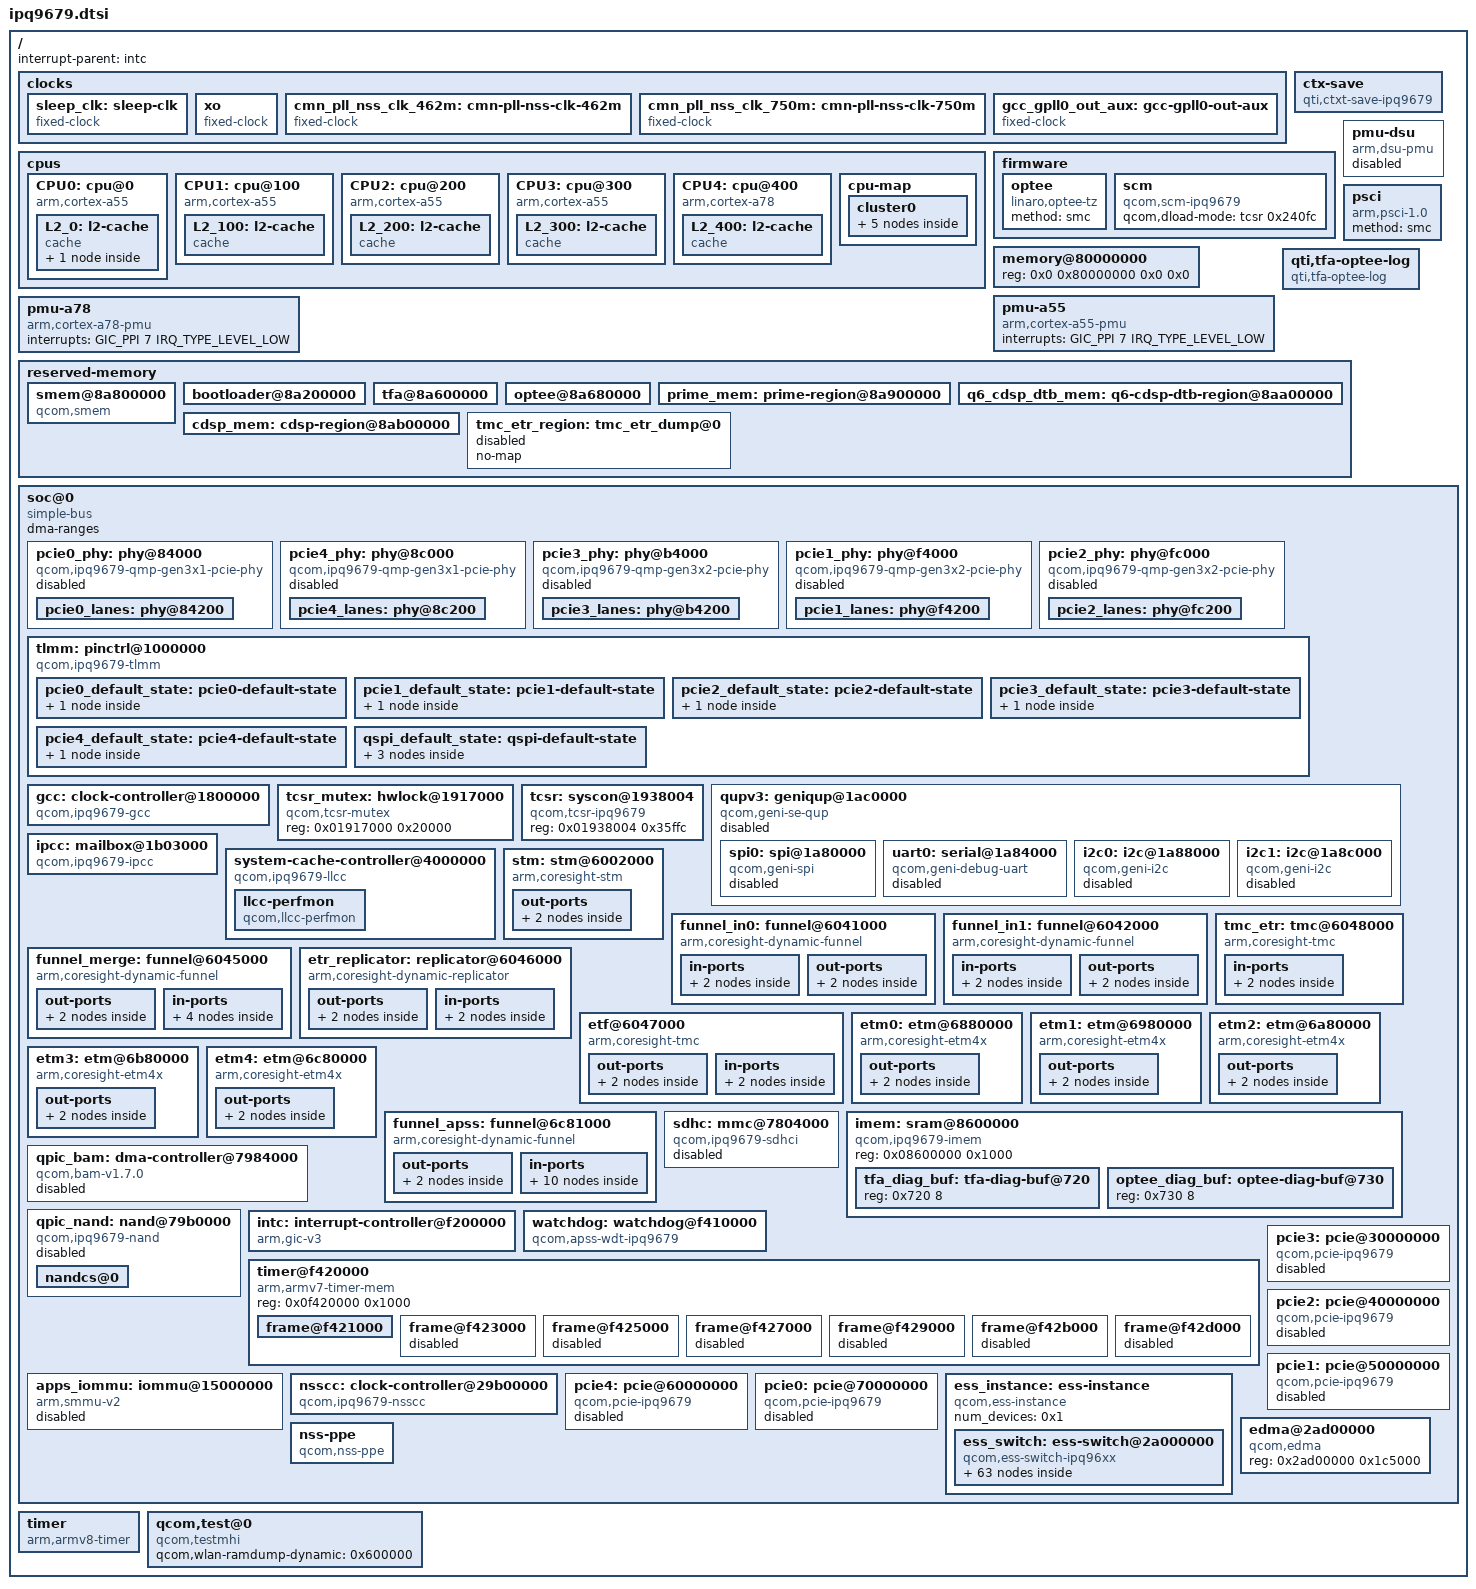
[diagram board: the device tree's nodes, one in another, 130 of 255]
// SPDX-License-Identifier: (GPL-2.0+ OR BSD-3-Clause)
/*
 * IPQ9679 device tree source
 *
 * Copyright (c) 2020-2021 The Linux Foundation. All rights reserved.
 * Copyright (c) Qualcomm Technologies, Inc. and/or its subsidiaries.
 */

#include <dt-bindings/clock/qcom,ipq9679-gcc.h>
#include <dt-bindings/clock/qcom,ipq9679-nsscc.h>
#include <dt-bindings/reset/qcom,ipq9679-gcc.h>
#include <dt-bindings/reset/qcom,ipq9679-nsscc.h>
#include <dt-bindings/interrupt-controller/arm-gic.h>
#include <dt-bindings/gpio/gpio.h>

/ {
	#address-cells = <2>;
	#size-cells = <2>;
	interrupt-parent = <&intc>;

	clocks {
		sleep_clk: sleep-clk {
			compatible = "fixed-clock";
			#clock-cells = <0>;
		};

		xo: xo {
			compatible = "fixed-clock";
			#clock-cells = <0>;
		};

		cmn_pll_nss_clk_462m: cmn-pll-nss-clk-462m {
			compatible = "fixed-clock";
			#clock-cells = <0>;
		};

		cmn_pll_nss_clk_750m: cmn-pll-nss-clk-750m {
			compatible = "fixed-clock";
			#clock-cells = <0>;
		};

		gcc_gpll0_out_aux: gcc-gpll0-out-aux {
			compatible = "fixed-clock";
			#clock-cells = <0>;
		};
	};

	cpus: cpus {
		#address-cells = <1>;
		#size-cells = <0>;

		CPU0: cpu@0 {
			device_type = "cpu";
			compatible = "arm,cortex-a55";
			reg = <0x0>;
			enable-method = "psci";
			next-level-cache = <&L2_0>;
			L2_0: l2-cache {
				compatible = "cache";
				cache-level = <2>;
				cache-unified;
				next-level-cache = <&L3_0>;
				L3_0: l3-cache {
					compatible = "cache";
					cache-level = <3>;
					cache-unified;
				};
			};
		};

		CPU1: cpu@100 {
			device_type = "cpu";
			compatible = "arm,cortex-a55";
			reg = <0x100>;
			enable-method = "psci";
			next-level-cache = <&L2_100>;
			L2_100: l2-cache {
				compatible = "cache";
				cache-level = <2>;
				cache-unified;
				next-level-cache = <&L3_0>;
			};
		};

		CPU2: cpu@200 {
			device_type = "cpu";
			compatible = "arm,cortex-a55";
			reg = <0x200>;
			enable-method = "psci";
			next-level-cache = <&L2_200>;
			L2_200: l2-cache {
				compatible = "cache";
				cache-level = <2>;
				cache-unified;
				next-level-cache = <&L3_0>;
			};
		};

		CPU3: cpu@300 {
			device_type = "cpu";
			compatible = "arm,cortex-a55";
			reg = <0x300>;
			enable-method = "psci";
			next-level-cache = <&L2_300>;
			L2_300: l2-cache {
				compatible = "cache";
				cache-level = <2>;
				cache-unified;
				next-level-cache = <&L3_0>;
			};
		};

		CPU4: cpu@400 {
			device_type = "cpu";
			compatible = "arm,cortex-a78";
			reg = <0x400>;
			enable-method = "psci";
			next-level-cache = <&L2_400>;
			L2_400: l2-cache {
				compatible = "cache";
				cache-level = <2>;
				cache-unified;
				next-level-cache = <&L3_0>;
			};
		};

		cpu-map {
			cluster0 {
				core0 {
					cpu = <&CPU0>;
				};

				core1 {
					cpu = <&CPU1>;
				};

				core2 {
					cpu = <&CPU2>;
				};

				core3 {
					cpu = <&CPU3>;
				};

				core4 {
					cpu = <&CPU4>;
				};
			};
		};
	};

	ctx-save {
		compatible = "qti,ctxt-save-ipq9679";
	};

	firmware {
		optee {
			compatible = "linaro,optee-tz";
			method = "smc";
		};

		scm {
			compatible = "qcom,scm-ipq9679", "qcom,scm";
			qcom,dload-mode = <&tcsr 0x240fc>;
		};
	};

	memory@80000000 {
		device_type = "memory";
		/* We expect the bootloader to fill in the size */
		reg = <0x0 0x80000000 0x0 0x0 >;
	};

	pmu-a55 {
		compatible = "arm,cortex-a55-pmu";
		interrupts = <GIC_PPI 7 IRQ_TYPE_LEVEL_LOW>;
	};

	pmu-a78 {
		compatible = "arm,cortex-a78-pmu";
		interrupts = <GIC_PPI 7 IRQ_TYPE_LEVEL_LOW>;
	};

	pmu-dsu {
		compatible = "arm,dsu-pmu";
		interrupts = <GIC_SPI 50 IRQ_TYPE_EDGE_RISING>;
		cpus = <&CPU0>, <&CPU1>, <&CPU2>, <&CPU3>, <&CPU4>;
		status = "disabled";
	};

	psci {
		compatible = "arm,psci-1.0";
		method = "smc";
	};

	qti,tfa-optee-log {
		compatible = "qti,tfa-optee-log";
		interrupts = <GIC_SPI 56 IRQ_TYPE_EDGE_RISING>;
		tfa-diag-info =<&tfa_diag_buf>;
		optee-diag-info =<&optee_diag_buf>;
	};

	reserved-memory {
		#address-cells = <2>;
		#size-cells = <2>;
		ranges;

		smem@8a800000 {
			compatible = "qcom,smem";
			reg = <0x0 0x8a100000 0x0 0x40000>;
			no-map;

			hwlocks = <&tcsr_mutex 3>;
		};

		bootloader@8a200000 {
			reg = <0x0 0x8a200000 0x0 0x400000>;
			no-map;
		};

		tfa@8a600000 {
			reg = <0x0 0x8a600000 0x0 0x80000>;
			no-map;
		};

		optee@8a680000 {
			reg = <0x0 0x8a680000 0x0 0x280000>;
			no-map;
		};

		prime_mem: prime-region@8a900000  {
			reg = <0x0 0x8a900000  0x0 0x100000>;
			no-map;
		};

		q6_cdsp_dtb_mem: q6-cdsp-dtb-region@8aa00000 {
			reg = <0x0 0x8aa00000 0x0 0x80000>;
			no-map;
		};

		cdsp_mem: cdsp-region@8ab00000 {
			reg = <0x0 0x8ab00000 0x0 0x2000000>;
			no-map;
		};

		tmc_etr_region: tmc_etr_dump@0 {
			no-map;
			status = "disabled";
		};
	};

	soc@0 {
		compatible = "simple-bus";
		#address-cells = <1>;
		#size-cells = <1>;
		ranges = <0 0 0 0xffffffff>;
		dma-ranges;

		pcie0_phy: phy@84000 {
			compatible = "qcom,ipq9679-qmp-gen3x1-pcie-phy",
				     "qcom,ipq9574-qmp-gen3x1-pcie-phy";
			reg = <0x00084000 0x1c0>; /* Serdes PLL */
			#address-cells = <1>;
			#size-cells = <1>;
			ranges;

			clocks = <&gcc GCC_PCIE0_AUX_CLK>,
				 <&gcc GCC_PCIE0_AHB_CLK>,
				 <&gcc GCC_ANOC_PCIE0_1LANE_M_CLK>,
				 <&gcc GCC_ANOC_PCIE0_1LANE_S_CLK>;
			clock-names = "aux", "cfg_ahb", "anoc_lane", "snoc_lane";

			assigned-clocks = <&gcc GCC_PCIE0_AUX_CLK>,
					  <&gcc GCC_PCIE0_AHB_CLK>,
					  <&gcc GCC_ANOC_PCIE0_1LANE_M_CLK>,
					  <&gcc GCC_ANOC_PCIE0_1LANE_S_CLK>;
			assigned-clock-rates = <20000000>,
					       <100000000>,
					       <200000000>,
					       <200000000>;

			resets = <&gcc GCC_PCIE0_PHY_BCR>,
				 <&gcc GCC_PCIE0PHY_PHY_BCR>;
			reset-names = "phy", "common";

			status = "disabled";

			pcie0_lanes: phy@84200 {
				reg = <0x00084200 0x170>, /* Serdes Tx0 */
				      <0x00084400 0x200>, /* Serdes Rx0 */
				      <0x00084600 0x1f0>, /* PCS: Lane0, COM, PCIE */
				      <0x00084a00 0x0f4>; /* pcs_misc */

				#phy-cells = <0>;

				clocks = <&gcc GCC_PCIE0_PIPE_CLK>;
				clock-names = "pipe0";
				clock-output-names = "gcc_pcie0_pipe_clk_src";
				#clock-cells = <0>;
			};
		};

		pcie4_phy: phy@8c000 {
			compatible = "qcom,ipq9679-qmp-gen3x1-pcie-phy",
				     "qcom,ipq9574-qmp-gen3x1-pcie-phy";
			reg = <0x0008c000 0x1c0>; /* Serdes PLL */
			#address-cells = <1>;
			#size-cells = <1>;
			ranges;

			clocks = <&gcc GCC_PCIE4_AUX_CLK>,
				 <&gcc GCC_PCIE4_AHB_CLK>,
				 <&gcc GCC_ANOC_PCIE4_1LANE_M_CLK>,
				 <&gcc GCC_ANOC_PCIE4_1LANE_S_CLK>;
			clock-names = "aux", "cfg_ahb", "anoc_lane", "snoc_lane";

			assigned-clocks = <&gcc GCC_PCIE4_AUX_CLK>,
					  <&gcc GCC_PCIE4_AHB_CLK>,
					  <&gcc GCC_ANOC_PCIE4_1LANE_M_CLK>,
					  <&gcc GCC_ANOC_PCIE4_1LANE_S_CLK>;
			assigned-clock-rates = <20000000>,
					       <100000000>,
					       <200000000>,
					       <200000000>;

			resets = <&gcc GCC_PCIE4_PHY_BCR>,
				 <&gcc GCC_PCIE4PHY_PHY_BCR>;
			reset-names = "phy", "common";

			status = "disabled";

			pcie4_lanes: phy@8c200 {
				reg = <0x0008c200 0x170>, /* Serdes Tx0 */
				      <0x0008c400 0x200>, /* Serdes Rx0 */
				      <0x0008c600 0x1f0>, /* PCS: Lane0, COM, PCIE */
				      <0x0008ca00 0x0f4>; /* pcs_misc */

				#phy-cells = <0>;

				clocks = <&gcc GCC_PCIE4_PIPE_CLK>;
				clock-names = "pipe0";
				clock-output-names = "gcc_pcie4_pipe_clk_src";
				#clock-cells = <0>;
			};
		};

		pcie3_phy: phy@b4000 {
			compatible = "qcom,ipq9679-qmp-gen3x2-pcie-phy",
				     "qcom,ipq9574-qmp-gen3x2-pcie-phy";
			reg = <0x000b4000 0x1c0>; /* Serdes PLL */
			#address-cells = <1>;
			#size-cells = <1>;
			ranges;

			clocks = <&gcc GCC_PCIE3_AUX_CLK>,
				 <&gcc GCC_PCIE3_AHB_CLK>,
				 <&gcc GCC_ANOC_PCIE3_2LANE_M_CLK>,
				 <&gcc GCC_ANOC_PCIE3_2LANE_S_CLK>;
			clock-names = "aux", "cfg_ahb", "anoc_lane", "snoc_lane";

			assigned-clocks = <&gcc GCC_PCIE3_AUX_CLK>,
					  <&gcc GCC_PCIE3_AHB_CLK>,
					  <&gcc GCC_ANOC_PCIE3_2LANE_M_CLK>,
					  <&gcc GCC_ANOC_PCIE3_2LANE_S_CLK>;
			assigned-clock-rates = <20000000>,
					       <100000000>,
					       <266666666>,
					       <200000000>;

			resets = <&gcc GCC_PCIE3_PHY_BCR>,
				 <&gcc GCC_PCIE3PHY_PHY_BCR>;
			reset-names = "phy", "common";

			status = "disabled";

			pcie3_lanes: phy@b4200 {
				reg = <0x000b4200 0x170>, /* Serdes Tx0 */
				      <0x000b4400 0x200>, /* Serdes Rx0 */
				      <0x000b4a00 0x1f0>, /* PCS: Lane0, COM, PCIE */
				      <0x000b4600 0x170>, /* Serdes Tx1 */
				      <0x000b4800 0x200>, /* Serdes Rx1 */
				      <0x000b4e00 0x0f4>; /* pcs_misc */

				#phy-cells = <0>;

				clocks = <&gcc GCC_PCIE3_PIPE_CLK>;
				clock-names = "pipe0";
				clock-output-names = "gcc_pcie3_pipe_clk_src";
				#clock-cells = <0>;
			};
		};

		pcie1_phy: phy@f4000 {
			compatible = "qcom,ipq9679-qmp-gen3x2-pcie-phy",
				     "qcom,ipq9574-qmp-gen3x2-pcie-phy";
			reg = <0x000f4000 0x1c0>; /* Serdes PLL */
			#address-cells = <1>;
			#size-cells = <1>;
			ranges;

			clocks = <&gcc GCC_PCIE1_AUX_CLK>,
				 <&gcc GCC_PCIE1_AHB_CLK>,
				 <&gcc GCC_ANOC_PCIE1_2LANE_M_CLK>,
				 <&gcc GCC_ANOC_PCIE1_2LANE_S_CLK>;
			clock-names = "aux", "cfg_ahb", "anoc_lane", "snoc_lane";

			assigned-clocks = <&gcc GCC_PCIE1_AUX_CLK>,
					  <&gcc GCC_PCIE1_AHB_CLK>,
					  <&gcc GCC_ANOC_PCIE1_2LANE_M_CLK>,
					  <&gcc GCC_ANOC_PCIE1_2LANE_S_CLK>;
			assigned-clock-rates = <20000000>,
					       <100000000>,
					       <266666666>,
					       <200000000>;

			resets = <&gcc GCC_PCIE1_PHY_BCR>,
				 <&gcc GCC_PCIE1PHY_PHY_BCR>;
			reset-names = "phy", "common";

			status = "disabled";

			pcie1_lanes: phy@f4200 {
				reg = <0x000f4200 0x170>, /* Serdes Tx0 */
				      <0x000f4400 0x200>, /* Serdes Rx0 */
				      <0x000f4a00 0x1f0>, /* PCS: Lane0, COM, PCIE */
				      <0x000f4600 0x170>, /* Serdes Tx1 */
				      <0x000f4800 0x200>, /* Serdes Rx1 */
				      <0x000f4e00 0x0f4>; /* pcs_misc */

				#phy-cells = <0>;

				clocks = <&gcc GCC_PCIE1_PIPE_CLK>;
				clock-names = "pipe0";
				clock-output-names = "gcc_pcie1_pipe_clk_src";
				#clock-cells = <0>;
			};
		};

		pcie2_phy: phy@fc000 {
			compatible = "qcom,ipq9679-qmp-gen3x2-pcie-phy",
				     "qcom,ipq9574-qmp-gen3x2-pcie-phy";
			reg = <0x000fc000 0x1c0>; /* Serdes PLL PCIE_2_CFG_QSERDES_PLL_QSERDES_PLL_G3X2_QMP_PLL */
			#address-cells = <1>;
			#size-cells = <1>;
			ranges;

			clocks = <&gcc GCC_PCIE2_AUX_CLK>,
				 <&gcc GCC_PCIE2_AHB_CLK>,
				 <&gcc GCC_ANOC_PCIE2_2LANE_M_CLK>,
				 <&gcc GCC_ANOC_PCIE2_2LANE_S_CLK>;
			clock-names = "aux", "cfg_ahb", "anoc_lane", "snoc_lane";

			assigned-clocks = <&gcc GCC_PCIE2_AUX_CLK>,
					  <&gcc GCC_PCIE2_AHB_CLK>,
					  <&gcc GCC_ANOC_PCIE2_2LANE_M_CLK>,
					  <&gcc GCC_ANOC_PCIE2_2LANE_S_CLK>;
			assigned-clock-rates = <20000000>,
					       <100000000>,
					       <266666666>,
					       <200000000>;

			resets = <&gcc GCC_PCIE2_PHY_BCR>,
				 <&gcc GCC_PCIE2PHY_PHY_BCR>;
			reset-names = "phy", "common";

			status = "disabled";

			pcie2_lanes: phy@fc200 {
				reg = <0x000fc200 0x170>, /* Serdes Tx0 */
				      <0x000fc400 0x200>, /* Serdes Rx0 */
				      <0x000fca00 0x1f0>, /* PCS: Lane0, COM, PCIE */
				      <0x000fc600 0x170>, /* Serdes Tx1 */
				      <0x000fc800 0x200>, /* Serdes Rx1 */
				      <0x000fce00 0x0f4>; /* pcs_misc */

				#phy-cells = <0>;

				clocks = <&gcc GCC_PCIE2_PIPE_CLK>;
				clock-names = "pipe0";
				clock-output-names = "gcc_pcie2_pipe_clk_src";
				#clock-cells = <0>;
			};
		};

		tlmm: pinctrl@1000000 {
			compatible = "qcom,ipq9679-tlmm";
			reg = <0x01000000 0x300000>;
			interrupts = <GIC_SPI 84 IRQ_TYPE_LEVEL_HIGH>;
			gpio-controller;
			#gpio-cells = <2>;
			gpio-ranges = <&tlmm 0 0 54>;
			interrupt-controller;
			#interrupt-cells = <2>;

			pcie0_default_state: pcie0-default-state {
				perst-n-pins {
					pins = "gpio25";
					function = "gpio";
					drive-strength = <2>;
					bias-pull-down;
					output-low;
				};
			};

			pcie1_default_state: pcie1-default-state {
				perst-n-pins {
					pins = "gpio28";
					function = "gpio";
					drive-strength = <2>;
					bias-pull-down;
					output-low;
				};
			};

			pcie2_default_state: pcie2-default-state {
				perst-n-pins {
					pins = "gpio52";
					function = "gpio";
					drive-strength = <2>;
					bias-pull-down;
					output-low;
				};
			};

			pcie3_default_state: pcie3-default-state {
				perst-n-pins {
					pins = "gpio41";
					function = "gpio";
					drive-strength = <2>;
					bias-pull-down;
					output-low;
				};
			};

			pcie4_default_state: pcie4-default-state {
				perst-n-pins {
					pins = "gpio31";
					function = "gpio";
					drive-strength = <2>;
					bias-pull-down;
					output-low;
				};
			};

			qspi_default_state: qspi-default-state {
				qspi_clk {
					pins = "gpio5";
					function = "qspi_clk";
					drive-strength = <8>;
					bias-pull-down;
				};

				qspi_cs {
					pins = "gpio4";
					function = "qspi_cs_n";
					drive-strength = <8>;
					bias-pull-up;
				};

				qspi_data {
					pins = "gpio0", "gpio1", "gpio2", "gpio3";
					function = "qspi_data";
					drive-strength = <8>;
					bias-pull-down;
				};
			};
		};

		gcc: clock-controller@1800000 {
			compatible = "qcom,ipq9679-gcc";
			reg = <0x01800000 0x40000>;

			clocks = <&xo>,
				 <&sleep_clk>;
			#clock-cells = <1>;
			#reset-cells = <1>;
			#power-domain-cells = <1>;
		};

		tcsr_mutex: hwlock@1917000 {
			compatible = "qcom,tcsr-mutex";
			reg = <0x01917000 0x20000>;
			#hwlock-cells = <1>;
		};

		tcsr: syscon@1938004 {
			compatible = "qcom,tcsr-ipq9679", "syscon";
			reg = <0x01938004 0x35ffc>;
		};

		qupv3: geniqup@1ac0000 {
			compatible = "qcom,geni-se-qup";
			reg = <0x01ac0000 0x2000>;
			clocks = <&gcc GCC_QUPV3_AHB_MST_CLK>,
				 <&gcc GCC_QUPV3_AHB_SLV_CLK>;
			clock-names = "m-ahb", "s-ahb";
			ranges;
			#address-cells = <1>;
			#size-cells = <1>;

			status = "disabled";

			spi0: spi@1a80000 {
				compatible = "qcom,geni-spi";
				reg = <0x01a80000 0x4000>;
				clocks = <&gcc GCC_QUPV3_SPI0_CLK>;
				clock-names = "se";
				interrupts = <GIC_SPI 339 IRQ_TYPE_LEVEL_HIGH>;
				assigned-clocks = <&gcc GCC_QUPV3_SPI0_CLK>;
				assigned-clock-rates = <50000000>;
				/* Use common SE TX FIFO depth configuration */
				qup-tx-fifo-depth = <0x20>;
				status = "disabled";
			};

			uart0: serial@1a84000 {
				compatible = "qcom,geni-debug-uart";
				reg = <0x01a84000 0x4000>;
				clocks = <&gcc GCC_QUPV3_UART0_CLK>;
				clock-names = "se";
				interrupts = <GIC_SPI 340 IRQ_TYPE_LEVEL_HIGH>;
				status = "disabled";
			};

			i2c0: i2c@1a88000 {
				compatible = "qcom,geni-i2c";
				reg = <0x1a88000 0x4000>;
				clocks = <&gcc GCC_QUPV3_I2C0_CLK>;
				clock-names = "se";
				clock-frequency = <400000>;
				interrupts = <GIC_SPI 341 IRQ_TYPE_LEVEL_HIGH>;
				assigned-clocks = <&gcc GCC_QUPV3_I2C0_CLK>;
				assigned-clock-rates = <64000000>;
				status = "disabled";
			};

			i2c1: i2c@1a8c000 {
				compatible = "qcom,geni-i2c";
				reg = <0x1a8c000 0x4000>;
				clocks = <&gcc GCC_QUPV3_I2C1_CLK>;
				clock-names = "se";
				clock-frequency = <400000>;
				interrupts = <GIC_SPI 342 IRQ_TYPE_LEVEL_HIGH>;
				assigned-clocks = <&gcc GCC_QUPV3_I2C1_CLK>;
				assigned-clock-rates = <64000000>;
				status = "disabled";
			};
		};

		ipcc: mailbox@1b03000 {
			compatible = "qcom,ipq9679-ipcc", "qcom,ipcc";
			reg = <0x01b03000 0x1000>;
			interrupts = <GIC_SPI 445 IRQ_TYPE_LEVEL_HIGH>;
			interrupt-controller;
			#interrupt-cells = <3>;
			#mbox-cells = <2>;
		};

		system-cache-controller@4000000 {
			compatible = "qcom,ipq9679-llcc";
			reg = <0x04000000 0x200000>, <0x04000000 0x200000>;
			reg-names = "llcc_base", "llcc_broadcast_base";
			interrupts = <GIC_SPI 68 IRQ_TYPE_LEVEL_HIGH>;

			llcc-perfmon {
				compatible = "qcom,llcc-perfmon";
			};
		};

		stm: stm@6002000 {
			compatible = "arm,coresight-stm", "arm,primecell";
			reg = <0x06002000 0x1000>,
				<0x09000000 0x1000000>;
			reg-names = "stm-base", "stm-stimulus-base";
			coresight-name = "coresight-stm";
			clocks = <&gcc GCC_QDSS_DAP_CLK>,
				 <&gcc GCC_QDSS_AT_CLK>;
			clock-names = "apb_pclk", "atclk";

			out-ports {
				port {
					stm_out: endpoint {
						remote-endpoint = <&funnel0_in7>;
					};
				};
			};
		};

		funnel_in0: funnel@6041000 {
			compatible = "arm,coresight-dynamic-funnel", "arm,primecell";
			reg = <0x06041000 0x1000>;
			reg-names = "funnel-base";
			coresight-name = "coresight-funnel-in0";
			clocks = <&gcc GCC_QDSS_DAP_CLK>,
				 <&gcc GCC_QDSS_AT_CLK>;
			clock-names = "apb_pclk", "atclk";

			in-ports {
				#address-cells = <1>;
				#size-cells = <0>;

				/*
				 * Port 0 - TME
				 * Port 2 - SNOC
				 * Port 3 - NSS
				 * Port 4 - CNOC
				 * Port 6 - TPDA QDSS
				 * Port 7 - STM_SS
				 */

				port@7 {
					reg = <7>;
					funnel0_in7: endpoint {
						remote-endpoint = <&stm_out>;
					};
				};
			};

			out-ports {
				port {
					funnel0_out: endpoint {
						remote-endpoint = <&merge_funnel_in0>;
					};
				};
			};
		};

		funnel_in1: funnel@6042000 {
			compatible = "arm,coresight-dynamic-funnel", "arm,primecell";
			reg = <0x06042000 0x1000>;
			reg-names = "funnel-base";
			coresight-name = "coresight-funnel-in1";
			clocks = <&gcc GCC_QDSS_DAP_CLK>,
				 <&gcc GCC_QDSS_AT_CLK>;
			clock-names = "apb_pclk", "atclk";

			in-ports {
				#address-cells = <1>;
				#size-cells = <0>;

				/*
				 * Port 0 - AGGRENOC
				 * Port 1 & 2 - DDRSS
				 * Port 3 - TPDA QDSS
				 * Port 4 - APSS
				 * Port 5 - TURING
				 */

				port@4 {
					reg = <4>;
					funnel1_in2: endpoint {
						remote-endpoint = <&apss_funnel_out>;
					};
				};
			};

			out-ports {
				port {
					funnel1_out: endpoint {
						remote-endpoint = <&merge_funnel_in1>;
					};
				};
			};

		};

		funnel_merge: funnel@6045000 {
			compatible = "arm,coresight-dynamic-funnel", "arm,primecell";
			reg = <0x06045000 0x1000>;
			reg-names = "funnel-base";
			coresight-name = "coresight-funnel-merge";
			clocks = <&gcc GCC_QDSS_DAP_CLK>,
				 <&gcc GCC_QDSS_AT_CLK>;
			clock-names = "apb_pclk", "atclk";

			out-ports {
				port {
					merge_funnel_out: endpoint {
						remote-endpoint = <&etf_in>;
					};
				};
			};

			in-ports {
				#address-cells = <1>;
				#size-cells = <0>;

				port@0 {
					reg = <0>;
					merge_funnel_in0: endpoint {
						remote-endpoint = <&funnel0_out>;
					};
				};

				port@1 {
					reg = <1>;
					merge_funnel_in1: endpoint {
						remote-endpoint = <&funnel1_out>;
					};
				};
			};

		};

		etr_replicator: replicator@6046000 {
			compatible = "arm,coresight-dynamic-replicator", "arm,primecell";
			reg = <0x06046000 0x1000>;
			reg-names = "replicator-base";
			coresight-name = "coresight-replicator";
			clocks = <&gcc GCC_QDSS_DAP_CLK>,
				 <&gcc GCC_QDSS_AT_CLK>;
			clock-names = "apb_pclk", "atclk";

			out-ports {
				#address-cells = <1>;
				#size-cells = <0>;

				port@0 {
					reg = <0>;
					etr_replicator_out0: endpoint {
						remote-endpoint = <&etr_in>;
					};
				};
			};

			in-ports {
				port {
					etr_replicator_in0: endpoint {
						remote-endpoint = <&etf_out>;
					};
				};
			};
		};

		etf@6047000 {
			compatible = "arm,coresight-tmc", "arm,primecell";
			reg = <0x06047000 0x1000>;
			reg-names = "tmc-base";
			coresight-name = "coresight-tmc-etf";
			arm,default-sink;
			clocks = <&gcc GCC_QDSS_DAP_CLK>;
			clock-names = "apb_pclk";

			out-ports {
				port {
					etf_out: endpoint {
						remote-endpoint = <&etr_replicator_in0>;
					};
				};
			};

			in-ports {
				port {
					etf_in: endpoint {
						remote-endpoint = <&merge_funnel_out>;
					};
				};
			};
		};

		tmc_etr: tmc@6048000 {
			compatible = "arm,coresight-tmc", "arm,primecell";
			reg = <0x06048000 0x1000>;
			reg-names = "tmc-base";
			interrupts = <GIC_SPI 403 IRQ_TYPE_EDGE_RISING>;
			interrupt-names = "byte-cntr-irq";
			arm,buffer-size = <0x100000>;
			arm,scatter-gather;
			memory-region = <&tmc_etr_region>;
			coresight-name = "coresight-tmc-etr";
			clocks = <&gcc GCC_QDSS_DAP_CLK>;
			clock-names = "apb_pclk";

			in-ports {
				port {
					etr_in: endpoint {
						remote-endpoint = <&etr_replicator_out0>;
					};
				};
			};
		};

		etm0: etm@6880000 {
			compatible = "arm,coresight-etm4x", "arm,primecell";
			reg = <0x06880000 0x1000>;
			coresight-name = "coresight-etm0";
			cpu = <&CPU0>;
			clocks = <&gcc GCC_QDSS_DAP_CLK>;
			clock-names = "apb_pclk";

			out-ports {
				port {
					etm0_out: endpoint {
						remote-endpoint = <&apss_funnel_in0>;
					};
				};
			};
		};

		etm1: etm@6980000 {
			compatible = "arm,coresight-etm4x", "arm,primecell";
			reg = <0x06980000 0x1000>;
			coresight-name = "coresight-etm1";
			cpu = <&CPU1>;
			clocks = <&gcc GCC_QDSS_DAP_CLK>;
			clock-names = "apb_pclk";

			out-ports {
				port {
					etm1_out: endpoint {
						remote-endpoint = <&apss_funnel_in1>;
					};
				};
			};
		};

		etm2: etm@6a80000 {
			compatible = "arm,coresight-etm4x", "arm,primecell";
			reg = <0x06a80000 0x1000>;
			coresight-name = "coresight-etm2";
			cpu = <&CPU2>;
			clocks = <&gcc GCC_QDSS_DAP_CLK>;
			clock-names = "apb_pclk";

			out-ports {
				port {
					etm2_out: endpoint {
						remote-endpoint = <&apss_funnel_in2>;
					};
				};
			};
		};

		etm3: etm@6b80000 {
			compatible = "arm,coresight-etm4x", "arm,primecell";
			reg = <0x06b80000 0x1000>;
			coresight-name = "coresight-etm3";
			cpu = <&CPU3>;
			clocks = <&gcc GCC_QDSS_DAP_CLK>;
			clock-names = "apb_pclk";

			out-ports {
				port {
					etm3_out: endpoint {
						remote-endpoint = <&apss_funnel_in3>;
					};
				};
			};
		};

		etm4: etm@6c80000 {
			compatible = "arm,coresight-etm4x", "arm,primecell";
			reg = <0x6c80000 0x1000>;
			coresight-name = "coresight-etm4";
			cpu = <&CPU4>;
			clocks = <&gcc GCC_QDSS_DAP_CLK>;
			clock-names = "apb_pclk";

			out-ports {
				port {
					etm4_out: endpoint {
						remote-endpoint = <&apss_funnel_in4>;
					};
				};
			};
		};

		funnel_apss: funnel@6c81000 {
			compatible = "arm,coresight-dynamic-funnel", "arm,primecell";
			reg = <0x06c81000 0x1000>;
			reg-names = "funnel-base";
			coresight-name = "coresight-funnel-apss";
			clocks = <&gcc GCC_QDSS_DAP_CLK>,
				 <&gcc GCC_QDSS_AT_CLK>;
			clock-names = "apb_pclk", "atclk";

			out-ports {
				port {
					apss_funnel_out: endpoint {
						remote-endpoint = <&funnel1_in2>;
					};
				};
			};

			in-ports {
				#address-cells = <1>;
				#size-cells = <0>;

				port@0 {
					reg = <0>;
					apss_funnel_in0: endpoint {
						remote-endpoint = <&etm0_out>;
					};
				};

				port@1 {
					reg = <1>;
					apss_funnel_in1: endpoint {
						remote-endpoint = <&etm1_out>;
					};
				};

				port@2 {
					reg = <2>;
					apss_funnel_in2: endpoint {
						remote-endpoint = <&etm2_out>;
					};
				};

				port@3 {
					reg = <3>;
					apss_funnel_in3: endpoint {
						remote-endpoint = <&etm3_out>;
					};
				};

				port@4 {
					reg = <4>;
					apss_funnel_in4: endpoint {
						remote-endpoint = <&etm4_out>;
					};
				};
			};
		};

		sdhc: mmc@7804000 {
			compatible = "qcom,ipq9679-sdhci", "qcom,sdhci-msm-v5";
			reg = <0x07804000 0x1000>, <0x07805000 0x1000>;

			interrupts = <GIC_SPI 116 IRQ_TYPE_LEVEL_HIGH>,
				     <GIC_SPI 119 IRQ_TYPE_LEVEL_HIGH>;
			interrupt-names = "hc_irq", "pwr_irq";

			clocks = <&gcc GCC_SDCC1_AHB_CLK>,
				 <&gcc GCC_SDCC1_APPS_CLK>,
				 <&xo>;
			clock-names = "iface", "core", "xo";

			status = "disabled";
		};

		imem: sram@8600000 {
			compatible = "qcom,ipq9679-imem", "qcom,imem";
			reg = <0x08600000 0x1000>;
			ranges = <0 0x08600000 0x1000>;

			#address-cells = <1>;
			#size-cells = <1>;

			/*
			 * First 4 bytes contains the Diag buffer address
			 * Second 4 bytes contains the Diag buffer size
			 */
			tfa_diag_buf: tfa-diag-buf@720 {
				reg = <0x720 8>;
			};

			/*
			 * First 4 bytes contains the Diag buffer address
			 * Second 4 bytes contains the Diag buffer size
			 */
			optee_diag_buf: optee-diag-buf@730 {
				reg = <0x730 8>;
			};

		};

		qpic_bam: dma-controller@7984000 {
			compatible = "qcom,bam-v1.7.0";
			reg = <0x7984000 0x1c000>;
			interrupts = <GIC_SPI 109 IRQ_TYPE_LEVEL_HIGH>;
			clocks = <&gcc GCC_QPIC_AHB_CLK>;
			clock-names = "bam_clk";
			#dma-cells = <1>;
			qcom,ee = <0>;
			qcom,bam-lite;
			status = "disabled";
		};

		qpic_nand: nand@79b0000 {
			compatible = "qcom,ipq9679-nand";
			reg = <0x79b0000 0x10000>;
			#address-cells = <1>;
			#size-cells = <0>;
			clocks = <&gcc GCC_QPIC_CLK>,
				 <&gcc GCC_QPIC_AHB_CLK>,
				 <&gcc GCC_QPIC_IO_MACRO_CLK>;
			clock-names = "core", "aon", "io_macro";

			dmas = <&qpic_bam 0>,
			       <&qpic_bam 1>,
			       <&qpic_bam 2>,
			       <&qpic_bam 3>;
			dma-names = "tx", "rx", "cmd", "sts";

			qcom,io_macro_max_clk = <320000000>;
			qcom,io_macro_clk_rates = <24000000 100000000 200000000 \
						   320000000>;

			pinctrl-0 = <&qspi_default_state>;
			pinctrl-names = "default";

			status = "disabled";
			nandcs@0 {
				reg = <0>;
				#address-cells = <1>;
				#size-cells = <1>;

				nand-ecc-strength = <8>;
				nand-ecc-step-size = <512>;
				nand-bus-width = <8>;
			};
		};

		intc: interrupt-controller@f200000 {
			compatible = "arm,gic-v3";
			reg = <0x0f200000 0x10000>, /* GICD */
			      <0x0f240000 0xa0000>; /* GICR * 5 regions */
			#interrupt-cells = <0x3>;
			interrupt-controller;
			#redistributor-regions = <1>;
			redistributor-stride = <0x0 0x20000>;
			interrupts = <GIC_PPI 9 IRQ_TYPE_LEVEL_HIGH>;
		};

		watchdog: watchdog@f410000 {
			compatible = "qcom,apss-wdt-ipq9679", "qcom,kpss-wdt";
			reg = <0x0f410000 0x1000>;
			interrupts = <GIC_SPI 0 IRQ_TYPE_EDGE_RISING>;
			clocks = <&sleep_clk>;
			timeout-sec = <30>;
		};

		timer@f420000 {
			compatible = "arm,armv7-timer-mem";
			reg = <0x0f420000 0x1000>;
			#address-cells = <1>;
			#size-cells = <1>;
			ranges;

			frame@f421000 {
				reg = <0x0f421000 0x1000>,
				      <0x0f422000 0x1000>;
				interrupts = <GIC_SPI 8 IRQ_TYPE_LEVEL_HIGH>,
					     <GIC_SPI 6 IRQ_TYPE_LEVEL_HIGH>;
				frame-number = <0>;
			};

			frame@f423000 {
				reg = <0x0f423000 0x1000>;
				interrupts = <GIC_SPI 9 IRQ_TYPE_LEVEL_HIGH>;
				frame-number = <1>;
				status = "disabled";
			};

			frame@f425000 {
				reg = <0x0f425000 0x1000>,
				      <0x0f426000 0x1000>;
				interrupts = <GIC_SPI 10 IRQ_TYPE_LEVEL_HIGH>;
				frame-number = <2>;
				status = "disabled";
			};

			frame@f427000 {
				reg = <0x0f427000 0x1000>;
				interrupts = <GIC_SPI 11 IRQ_TYPE_LEVEL_HIGH>;
				frame-number = <3>;
				status = "disabled";
			};

			frame@f429000 {
				reg = <0x0f429000 0x1000>;
				interrupts = <GIC_SPI 12 IRQ_TYPE_LEVEL_HIGH>;
				frame-number = <4>;
				status = "disabled";
			};

			frame@f42b000 {
				reg = <0x0f42b000 0x1000>;
				interrupts = <GIC_SPI 13 IRQ_TYPE_LEVEL_HIGH>;
				frame-number = <5>;
				status = "disabled";
			};

			frame@f42d000 {
				reg = <0x0f42d000 0x1000>;
				interrupts = <GIC_SPI 14 IRQ_TYPE_LEVEL_HIGH>;
				frame-number = <6>;
				status = "disabled";
			};
		};

		apps_iommu: iommu@15000000 {
			compatible = "arm,smmu-v2";
			reg = <0x15000000 0x40000>;

			interrupts = <GIC_SPI 636 IRQ_TYPE_LEVEL_HIGH>,
				     <GIC_SPI 639 IRQ_TYPE_LEVEL_HIGH>,
				     <GIC_SPI 640 IRQ_TYPE_LEVEL_HIGH>,
				     <GIC_SPI 641 IRQ_TYPE_LEVEL_HIGH>,
				     <GIC_SPI 642 IRQ_TYPE_LEVEL_HIGH>,
				     <GIC_SPI 643 IRQ_TYPE_LEVEL_HIGH>,
				     <GIC_SPI 644 IRQ_TYPE_LEVEL_HIGH>,
				     <GIC_SPI 645 IRQ_TYPE_LEVEL_HIGH>,
				     <GIC_SPI 646 IRQ_TYPE_LEVEL_HIGH>,
				     <GIC_SPI 647 IRQ_TYPE_LEVEL_HIGH>,
				     <GIC_SPI 648 IRQ_TYPE_LEVEL_HIGH>,
				     <GIC_SPI 649 IRQ_TYPE_LEVEL_HIGH>,
				     <GIC_SPI 650 IRQ_TYPE_LEVEL_HIGH>,
				     <GIC_SPI 651 IRQ_TYPE_LEVEL_HIGH>,
				     <GIC_SPI 652 IRQ_TYPE_LEVEL_HIGH>,
				     <GIC_SPI 653 IRQ_TYPE_LEVEL_HIGH>,
				     <GIC_SPI 654 IRQ_TYPE_LEVEL_HIGH>,
				     <GIC_SPI 655 IRQ_TYPE_LEVEL_HIGH>,
				     <GIC_SPI 656 IRQ_TYPE_LEVEL_HIGH>,
				     <GIC_SPI 657 IRQ_TYPE_LEVEL_HIGH>,
				     <GIC_SPI 658 IRQ_TYPE_LEVEL_HIGH>,
				     <GIC_SPI 659 IRQ_TYPE_LEVEL_HIGH>,
				     <GIC_SPI 660 IRQ_TYPE_LEVEL_HIGH>,
				     <GIC_SPI 661 IRQ_TYPE_LEVEL_HIGH>,
				     <GIC_SPI 662 IRQ_TYPE_LEVEL_HIGH>,
				     <GIC_SPI 663 IRQ_TYPE_LEVEL_HIGH>,
				     <GIC_SPI 664 IRQ_TYPE_LEVEL_HIGH>,
				     <GIC_SPI 665 IRQ_TYPE_LEVEL_HIGH>,
				     <GIC_SPI 666 IRQ_TYPE_LEVEL_HIGH>,
				     <GIC_SPI 667 IRQ_TYPE_LEVEL_HIGH>,
				     <GIC_SPI 668 IRQ_TYPE_LEVEL_HIGH>,
				     <GIC_SPI 669 IRQ_TYPE_LEVEL_HIGH>,
				     <GIC_SPI 670 IRQ_TYPE_LEVEL_HIGH>;

			#iommu-cells = <1>;
			#global-interrupts = <1>;

			status = "disabled";
		};

		nsscc: clock-controller@29b00000 {
			compatible = "qcom,ipq9679-nsscc";
			reg = <0x29b00000 0x100000>;
			clocks = <&xo>,
				 <&cmn_pll_nss_clk_750m>,
				 <&cmn_pll_nss_clk_462m>,
				 <&gcc_gpll0_out_aux>,
				 <0>,
				 <0>,
				 <0>,
				 <0>,
				 <0>,
				 <0>;
			clock-names = "xo",
				      "nss",
				      "ppe",
				      "gpll0_out",
				      "uniphy0_rx",
				      "uniphy0_tx",
				      "uniphy1_rx",
				      "uniphy1_tx",
				      "uniphy2_rx",
				      "uniphy2_tx";
			#clock-cells = <1>;
			#reset-cells = <1>;
			#interconnect-cells = <1>;
		};

		pcie3: pcie@30000000 {
			compatible = "qcom,pcie-ipq9679";
			reg =  <0x30000000 0xf1d>,
			       <0x30000f20 0xa8>,
			       <0x30001000 0x1000>,
			       <0x000b0000 0x3000>,
			       <0x30100000 0x1000>;
			reg-names = "dbi", "elbi", "atu", "parf", "config";
			device_type = "pci";
			linux,pci-domain = <3>;
			bus-range = <0x00 0xff>;
			num-lanes = <2>;
			#address-cells = <3>;
			#size-cells = <2>;

			ranges = <0x81000000 0 0x30200000 0x30200000 0 0x00100000>,   /* downstream I/O */
				 <0x82000000 0 0x30300000 0x30300000 0 0x0fd00000>; /* non-prefetchable memory */

			#interrupt-cells = <1>;
			interrupt-map-mask = <0 0 0 0x7>;
			interrupt-map = <0 0 0 1 &intc 0 505 IRQ_TYPE_LEVEL_HIGH>, /* int_a */
					<0 0 0 2 &intc 0 506 IRQ_TYPE_LEVEL_HIGH>, /* int_b */
					<0 0 0 3 &intc 0 507 IRQ_TYPE_LEVEL_HIGH>, /* int_c */
					<0 0 0 4 &intc 0 508 IRQ_TYPE_LEVEL_HIGH>; /* int_d */

			interrupts = <GIC_SPI 504 IRQ_TYPE_LEVEL_HIGH>,
				     <GIC_SPI 496 IRQ_TYPE_LEVEL_HIGH>;
			interrupt-names = "global_irq", "msi";

			clocks = <&gcc GCC_PCIE3_AXI_M_CLK>,
				 <&gcc GCC_PCIE3_AXI_S_CLK>,
				 <&gcc GCC_PCIE3_AHB_CLK>,
				 <&gcc GCC_PCIE3_AUX_CLK>,
				 <&gcc GCC_PCIE3_AXI_S_BRIDGE_CLK>,
				 <&gcc GCC_PCIE3_RCHNG_CLK>;

			clock-names = "axi_m",
				      "axi_s",
				      "ahb",
				      "aux",
				      "axi_bridge",
				      "rchng";

			assigned-clocks = <&gcc GCC_PCIE3_AUX_CLK>,
					  <&gcc GCC_PCIE3_AXI_M_CLK>,
					  <&gcc GCC_PCIE3_AXI_S_BRIDGE_CLK>,
					  <&gcc GCC_PCIE3_AXI_S_CLK>,
					  <&gcc GCC_PCIE3_RCHNG_CLK>;

			assigned-clock-rates = <20000000>,
					       <266666666>,
					       <200000000>,
					       <200000000>,
					       <100000000>;

			resets = <&gcc GCC_PCIE3_PIPE_ARES>,
				 <&gcc GCC_PCIE3_CORE_STICKY_RESET>,
				 <&gcc GCC_PCIE3_AXI_M_ARES>,
				 <&gcc GCC_PCIE3_AXI_S_ARES>,
				 <&gcc GCC_PCIE3_AXI_M_STICKY_RESET>,
				 <&gcc GCC_PCIE3_AXI_S_STICKY_RESET>,
				 <&gcc GCC_PCIE3_AHB_ARES>,
				 <&gcc GCC_PCIE3_AUX_ARES>;

			reset-names = "pipe",
				      "sticky",
				      "axi_m",
				      "axi_s",
				      "axi_m_sticky",
				      "axi_s_sticky",
				      "ahb",
				      "aux";

			pinctrl-0 = <&pcie3_default_state>;
			pinctrl-names = "default";

			phys = <&pcie3_lanes>;
			phy-names = "pciephy";

			status = "disabled";
		};

		pcie2: pcie@40000000 {
			compatible = "qcom,pcie-ipq9679";
			reg =  <0x40000000 0xf1d>,
			       <0x40000f20 0xa8>,
			       <0x40001000 0x1000>,
			       <0x000f8000 0x3000>,
			       <0x40100000 0x1000>;
			reg-names = "dbi", "elbi", "atu", "parf", "config";
			device_type = "pci";
			linux,pci-domain = <2>;
			bus-range = <0x00 0xff>;
			num-lanes = <2>;
			#address-cells = <3>;
			#size-cells = <2>;
			qcom,aspm-supported;

			ranges = <0x81000000 0 0x40200000 0x40200000 0 0x00100000>,   /* downstream I/O */
				 <0x82000000 0 0x40300000 0x40300000 0 0x0fd00000>; /* non-prefetchable memory */

			#interrupt-cells = <1>;
			interrupt-map-mask = <0 0 0 0x7>;
			interrupt-map = <0 0 0 1 &intc 0 479 IRQ_TYPE_LEVEL_HIGH>, /* int_a */
					<0 0 0 2 &intc 0 480 IRQ_TYPE_LEVEL_HIGH>, /* int_b */
					<0 0 0 3 &intc 0 481 IRQ_TYPE_LEVEL_HIGH>, /* int_c */
					<0 0 0 4 &intc 0 482 IRQ_TYPE_LEVEL_HIGH>; /* int_d */

			interrupts = <GIC_SPI 478 IRQ_TYPE_LEVEL_HIGH>,
				     <GIC_SPI 470 IRQ_TYPE_LEVEL_HIGH>;
			interrupt-names = "global_irq", "msi";

			clocks = <&gcc GCC_PCIE2_AXI_M_CLK>,
				 <&gcc GCC_PCIE2_AXI_S_CLK>,
				 <&gcc GCC_PCIE2_AHB_CLK>,
				 <&gcc GCC_PCIE2_AUX_CLK>,
				 <&gcc GCC_PCIE2_AXI_S_BRIDGE_CLK>,
				 <&gcc GCC_PCIE2_RCHNG_CLK>;

			clock-names = "axi_m",
				      "axi_s",
				      "ahb",
				      "aux",
				      "axi_bridge",
				      "rchng";

			assigned-clocks = <&gcc GCC_PCIE2_AUX_CLK>,
					  <&gcc GCC_PCIE2_AXI_M_CLK>,
					  <&gcc GCC_PCIE2_AXI_S_BRIDGE_CLK>,
					  <&gcc GCC_PCIE2_AXI_S_CLK>,
					  <&gcc GCC_PCIE2_RCHNG_CLK>;

			assigned-clock-rates = <20000000>,
					       <266666666>,
					       <200000000>,
					       <200000000>,
					       <100000000>;

			resets = <&gcc GCC_PCIE2_PIPE_ARES>,
				 <&gcc GCC_PCIE2_CORE_STICKY_RESET>,
				 <&gcc GCC_PCIE2_AXI_M_ARES>,
				 <&gcc GCC_PCIE2_AXI_S_ARES>,
				 <&gcc GCC_PCIE2_AXI_M_STICKY_RESET>,
				 <&gcc GCC_PCIE2_AXI_S_STICKY_RESET>,
				 <&gcc GCC_PCIE2_AHB_ARES>,
				 <&gcc GCC_PCIE2_AUX_ARES>;

			reset-names = "pipe",
				      "sticky",
				      "axi_m",
				      "axi_s",
				      "axi_m_sticky",
				      "axi_s_sticky",
				      "ahb",
				      "aux";

			pinctrl-0 = <&pcie2_default_state>;
			pinctrl-names = "default";

			phys = <&pcie2_lanes>;
			phy-names = "pciephy";

			status = "disabled";
		};

		pcie1: pcie@50000000 {
			compatible = "qcom,pcie-ipq9679";
			reg =  <0x50000000 0xf1d>,
			       <0x50000f20 0xa8>,
			       <0x50001000 0x1000>,
			       <0x000f0000 0x3000>,
			       <0x50100000 0x1000>;
			reg-names = "dbi", "elbi", "atu", "parf", "config";
			device_type = "pci";
			linux,pci-domain = <1>;
			bus-range = <0x00 0xff>;
			num-lanes = <2>;
			#address-cells = <3>;
			#size-cells = <2>;

			ranges = <0x81000000 0 0x50200000 0x50200000 0 0x00100000>,   /* downstream I/O */
				 <0x82000000 0 0x50300000 0x50300000 0 0x0fd00000>; /* non-prefetchable memory */

			#interrupt-cells = <1>;
			interrupt-map-mask = <0 0 0 0x7>;
			interrupt-map = <0 0 0 1 &intc 0 464 IRQ_TYPE_LEVEL_HIGH>, /* int_a */
					<0 0 0 2 &intc 0 465 IRQ_TYPE_LEVEL_HIGH>, /* int_b */
					<0 0 0 3 &intc 0 466 IRQ_TYPE_LEVEL_HIGH>, /* int_c */
					<0 0 0 4 &intc 0 467 IRQ_TYPE_LEVEL_HIGH>; /* int_d */

			interrupts = <GIC_SPI 463 IRQ_TYPE_LEVEL_HIGH>,
				     <GIC_SPI 455 IRQ_TYPE_LEVEL_HIGH>;
			interrupt-names = "global_irq", "msi";

			clocks = <&gcc GCC_PCIE1_AXI_M_CLK>,
				 <&gcc GCC_PCIE1_AXI_S_CLK>,
				 <&gcc GCC_PCIE1_AHB_CLK>,
				 <&gcc GCC_PCIE1_AUX_CLK>,
				 <&gcc GCC_PCIE1_AXI_S_BRIDGE_CLK>,
				 <&gcc GCC_PCIE1_RCHNG_CLK>;

			clock-names = "axi_m",
				      "axi_s",
				      "ahb",
				      "aux",
				      "axi_bridge",
				      "rchng";

			assigned-clocks = <&gcc GCC_PCIE1_AUX_CLK>,
					  <&gcc GCC_PCIE1_AXI_M_CLK>,
					  <&gcc GCC_PCIE1_AXI_S_BRIDGE_CLK>,
					  <&gcc GCC_PCIE1_AXI_S_CLK>,
					  <&gcc GCC_PCIE1_RCHNG_CLK>;

			assigned-clock-rates = <20000000>,
					       <266666666>,
					       <200000000>,
					       <200000000>,
					       <100000000>;

			resets = <&gcc GCC_PCIE1_PIPE_ARES>,
				 <&gcc GCC_PCIE1_CORE_STICKY_RESET>,
				 <&gcc GCC_PCIE1_AXI_M_ARES>,
				 <&gcc GCC_PCIE1_AXI_S_ARES>,
				 <&gcc GCC_PCIE1_AXI_M_STICKY_RESET>,
				 <&gcc GCC_PCIE1_AXI_S_STICKY_RESET>,
				 <&gcc GCC_PCIE1_AHB_ARES>,
				 <&gcc GCC_PCIE1_AUX_ARES>;

			reset-names = "pipe",
				      "sticky",
				      "axi_m",
				      "axi_s",
				      "axi_m_sticky",
				      "axi_s_sticky",
				      "ahb",
				      "aux";

			pinctrl-0 = <&pcie1_default_state>;
			pinctrl-names = "default";

			phys = <&pcie1_lanes>;
			phy-names = "pciephy";

			status = "disabled";
		};

		pcie4: pcie@60000000 {
			compatible = "qcom,pcie-ipq9679";
			reg =  <0x60000000 0xf1d>,
			       <0x60000f20 0xa8>,
			       <0x60001000 0x1000>,
			       <0x00088000 0x3000>,
			       <0x60100000 0x1000>;
			reg-names = "dbi", "elbi", "atu", "parf", "config";
			device_type = "pci";
			linux,pci-domain = <4>;
			bus-range = <0x00 0xff>;
			num-lanes = <1>;
			#address-cells = <3>;
			#size-cells = <2>;

			ranges = <0x81000000 0 0x60200000 0x60200000 0 0x00100000>,   /* downstream I/O */
				 <0x82000000 0 0x60300000 0x60300000 0 0x0fd00000>; /* non-prefetchable memory */

			#interrupt-cells = <1>;
			interrupt-map-mask = <0 0 0 0x7>;
			interrupt-map = <0 0 0 1 &intc 0 520 IRQ_TYPE_LEVEL_HIGH>, /* int_a */
					<0 0 0 2 &intc 0 521 IRQ_TYPE_LEVEL_HIGH>, /* int_b */
					<0 0 0 3 &intc 0 522 IRQ_TYPE_LEVEL_HIGH>, /* int_c */
					<0 0 0 4 &intc 0 523 IRQ_TYPE_LEVEL_HIGH>; /* int_d */

			interrupts = <GIC_SPI 519 IRQ_TYPE_LEVEL_HIGH>,
				     <GIC_SPI 511 IRQ_TYPE_LEVEL_HIGH>;
			interrupt-names = "global_irq", "msi";

			clocks = <&gcc GCC_PCIE4_AXI_M_CLK>,
				 <&gcc GCC_PCIE4_AXI_S_CLK>,
				 <&gcc GCC_PCIE4_AHB_CLK>,
				 <&gcc GCC_PCIE4_AUX_CLK>,
				 <&gcc GCC_PCIE4_AXI_S_BRIDGE_CLK>,
				 <&gcc GCC_PCIE4_RCHNG_CLK>;

			clock-names = "axi_m",
				      "axi_s",
				      "ahb",
				      "aux",
				      "axi_bridge",
				      "rchng";

			assigned-clocks = <&gcc GCC_PCIE4_AUX_CLK>,
					  <&gcc GCC_PCIE4_AXI_M_CLK>,
					  <&gcc GCC_PCIE4_AXI_S_BRIDGE_CLK>,
					  <&gcc GCC_PCIE4_AXI_S_CLK>,
					  <&gcc GCC_PCIE4_RCHNG_CLK>;

			assigned-clock-rates = <20000000>,
					       <200000000>,
					       <200000000>,
					       <200000000>,
					       <100000000>;

			resets = <&gcc GCC_PCIE4_PIPE_ARES>,
				 <&gcc GCC_PCIE4_CORE_STICKY_RESET>,
				 <&gcc GCC_PCIE4_AXI_M_ARES>,
				 <&gcc GCC_PCIE4_AXI_S_ARES>,
				 <&gcc GCC_PCIE4_AXI_M_STICKY_RESET>,
				 <&gcc GCC_PCIE4_AXI_S_STICKY_RESET>,
				 <&gcc GCC_PCIE4_AHB_ARES>,
				 <&gcc GCC_PCIE4_AUX_ARES>;

			reset-names = "pipe",
				      "sticky",
				      "axi_m",
				      "axi_s",
				      "axi_m_sticky",
				      "axi_s_sticky",
				      "ahb",
				      "aux";

			pinctrl-0 = <&pcie4_default_state>;
			pinctrl-names = "default";

			phys = <&pcie4_lanes>;
			phy-names = "pciephy";

			status = "disabled";
		};

		pcie0: pcie@70000000 {
			compatible = "qcom,pcie-ipq9679";
			reg =  <0x70000000 0xf1d>,
			       <0x70000f20 0xa8>,
			       <0x70001000 0x1000>,
			       <0x00080000 0x3000>,
			       <0x70100000 0x1000>;
			reg-names = "dbi", "elbi", "atu", "parf", "config";
			device_type = "pci";
			linux,pci-domain = <0>;
			bus-range = <0x00 0xff>;
			num-lanes = <1>;
			#address-cells = <3>;
			#size-cells = <2>;

			ranges = <0x81000000 0 0x70200000 0x70200000 0 0x00100000>,   /* downstream I/O */
				 <0x82000000 0 0x70300000 0x70300000 0 0x0fd00000>; /* non-prefetchable memory */

			#interrupt-cells = <1>;
			interrupt-map-mask = <0 0 0 0x7>;
			interrupt-map = <0 0 0 1 &intc 0 434 IRQ_TYPE_LEVEL_HIGH>, /* int_a */
					<0 0 0 2 &intc 0 435 IRQ_TYPE_LEVEL_HIGH>, /* int_b */
					<0 0 0 3 &intc 0 436 IRQ_TYPE_LEVEL_HIGH>, /* int_c */
					<0 0 0 4 &intc 0 437 IRQ_TYPE_LEVEL_HIGH>; /* int_d */

			interrupts = <GIC_SPI 433 IRQ_TYPE_LEVEL_HIGH>,
				     <GIC_SPI 425 IRQ_TYPE_LEVEL_HIGH>;
			interrupt-names = "global_irq", "msi";

			clocks = <&gcc GCC_PCIE0_AXI_M_CLK>,
				 <&gcc GCC_PCIE0_AXI_S_CLK>,
				 <&gcc GCC_PCIE0_AHB_CLK>,
				 <&gcc GCC_PCIE0_AUX_CLK>,
				 <&gcc GCC_PCIE0_AXI_S_BRIDGE_CLK>,
				 <&gcc GCC_PCIE0_RCHNG_CLK>;

			clock-names = "axi_m",
				      "axi_s",
				      "ahb",
				      "aux",
				      "axi_bridge",
				      "rchng";

			assigned-clocks = <&gcc GCC_PCIE0_AUX_CLK>,
					  <&gcc GCC_PCIE0_AXI_M_CLK>,
					  <&gcc GCC_PCIE0_AXI_S_BRIDGE_CLK>,
					  <&gcc GCC_PCIE0_AXI_S_CLK>,
					  <&gcc GCC_PCIE0_RCHNG_CLK>;

			assigned-clock-rates = <20000000>,
					       <200000000>,
					       <200000000>,
					       <200000000>,
					       <100000000>;

			resets = <&gcc GCC_PCIE0_PIPE_ARES>,
				 <&gcc GCC_PCIE0_CORE_STICKY_RESET>,
				 <&gcc GCC_PCIE0_AXI_M_ARES>,
				 <&gcc GCC_PCIE0_AXI_S_ARES>,
				 <&gcc GCC_PCIE0_AXI_M_STICKY_RESET>,
				 <&gcc GCC_PCIE0_AXI_S_STICKY_RESET>,
				 <&gcc GCC_PCIE0_AHB_ARES>,
				 <&gcc GCC_PCIE0_AUX_ARES>;

			reset-names = "pipe",
				      "sticky",
				      "axi_m",
				      "axi_s",
				      "axi_m_sticky",
				      "axi_s_sticky",
				      "ahb",
				      "aux";

			pinctrl-0 = <&pcie0_default_state>;
			pinctrl-names = "default";

			phys = <&pcie0_lanes>;
			phy-names = "pciephy";

			status = "disabled";
		};

		ess_instance: ess-instance {
			compatible = "qcom,ess-instance";
			num_devices = <0x1>;

			ess_switch: ess-switch@2a000000 {
				compatible = "qcom,ess-switch-ipq96xx";
				reg = <0x2a000000 0x1000000>;
				switch_access_mode = "local bus";
				switch_cpu_bmp = <0x1>;  /* cpu port bitmap */
				switch_inner_bmp = <0x180>; /* inner port bitmap */
				switch_lan_bmp = <0x3e>; /* lan port bitmap */
				switch_wan_bmp = <0x40>; /* wan port bitmap */
				bm_tick_mode = <0>; /* bm tick mode */
				tm_tick_mode = <0>; /* tm tick mode */
				clocks = <&gcc GCC_CMN_12GPLL_AHB_CLK>,
					 <&gcc GCC_CMN_12GPLL_SYS_CLK>,
					 <&gcc GCC_UNIPHY0_AHB_CLK>,
					 <&gcc GCC_UNIPHY0_SYS_CLK>,
					 <&gcc GCC_UNIPHY1_AHB_CLK>,
					 <&gcc GCC_UNIPHY1_SYS_CLK>,
					 <&gcc GCC_UNIPHY2_AHB_CLK>,
					 <&gcc GCC_UNIPHY2_SYS_CLK>,
					 <&gcc GCC_NSSNOC_NSSCC_CLK>,
					 <&gcc GCC_NSSCC_CLK>,
					 <&gcc GCC_NSSNOC_SNOC_1_CLK>,
					 <&gcc GCC_NSSNOC_SNOC_CLK>,
					 <&nsscc NSS_CC_PORT1_MAC_CLK>,
					 <&nsscc NSS_CC_PORT2_MAC_CLK>,
					 <&nsscc NSS_CC_PORT3_MAC_CLK>,
					 <&nsscc NSS_CC_PORT4_MAC_CLK>,
					 <&nsscc NSS_CC_PORT5_MAC_CLK>,
					 <&nsscc NSS_CC_PORT6_MAC_CLK>,
					 <&nsscc NSS_CC_PPE_SWITCH_CLK>,
					 <&nsscc NSS_CC_PPE_SWITCH_CFG_CLK>,
					 <&nsscc NSS_CC_NSSNOC_PPE_CLK>,
					 <&nsscc NSS_CC_NSSNOC_PPE_CFG_CLK>,
					 <&nsscc NSS_CC_PPE_EDMA_CLK>,
					 <&nsscc NSS_CC_PPE_EDMA_CFG_CLK>,
					 <&nsscc NSS_CC_PPE_SWITCH_IPE_CLK>,
					 <&nsscc NSS_CC_PPE_SWITCH_BTQ_CLK>,
					 <&nsscc NSS_CC_PORT1_RX_CLK>,
					 <&nsscc NSS_CC_PORT1_TX_CLK>,
					 <&nsscc NSS_CC_PORT2_RX_CLK>,
					 <&nsscc NSS_CC_PORT2_TX_CLK>,
					 <&nsscc NSS_CC_PORT3_RX_CLK>,
					 <&nsscc NSS_CC_PORT3_TX_CLK>,
					 <&nsscc NSS_CC_PORT4_RX_CLK>,
					 <&nsscc NSS_CC_PORT4_TX_CLK>,
					 <&nsscc NSS_CC_PORT5_RX_CLK>,
					 <&nsscc NSS_CC_PORT5_TX_CLK>,
					 <&nsscc NSS_CC_PORT6_RX_CLK>,
					 <&nsscc NSS_CC_PORT6_TX_CLK>,
					 <&nsscc NSS_CC_UNIPHY_PORT1_RX_CLK>,
					 <&nsscc NSS_CC_UNIPHY_PORT1_TX_CLK>,
					 <&nsscc NSS_CC_UNIPHY_PORT2_RX_CLK>,
					 <&nsscc NSS_CC_UNIPHY_PORT2_TX_CLK>,
					 <&nsscc NSS_CC_UNIPHY_PORT3_RX_CLK>,
					 <&nsscc NSS_CC_UNIPHY_PORT3_TX_CLK>,
					 <&nsscc NSS_CC_UNIPHY_PORT4_RX_CLK>,
					 <&nsscc NSS_CC_UNIPHY_PORT4_TX_CLK>,
					 <&nsscc NSS_CC_UNIPHY_PORT5_RX_CLK>,
					 <&nsscc NSS_CC_UNIPHY_PORT5_TX_CLK>,
					 <&nsscc NSS_CC_UNIPHY_PORT6_RX_CLK>,
					 <&nsscc NSS_CC_UNIPHY_PORT6_TX_CLK>;
				clock-names = "cmn_ahb_clk",
					      "cmn_sys_clk",
					      "uniphy0_ahb_clk",
					      "uniphy0_sys_clk",
					      "uniphy1_ahb_clk",
					      "uniphy1_sys_clk",
					      "uniphy2_ahb_clk",
					      "uniphy2_sys_clk",
					      "gcc_nssnoc_nsscc_clk",
					      "gcc_nsscc_clk",
					      "gcc_nssnoc_snoc_1_clk",
					      "gcc_nssnoc_snoc_clk",
					      "port1_mac_clk",
					      "port2_mac_clk",
					      "port3_mac_clk",
					      "port4_mac_clk",
					      "port5_mac_clk",
					      "port6_mac_clk",
					      "nss_ppe_clk",
					      "nss_ppe_cfg_clk",
					      "nssnoc_ppe_clk",
					      "nssnoc_ppe_cfg_clk",
					      "nss_edma_clk",
					      "nss_edma_cfg_clk",
					      "nss_ppe_ipe_clk",
					      "nss_ppe_btq_clk",
					      "nss_port1_rx_clk",
					      "nss_port1_tx_clk",
					      "nss_port2_rx_clk",
					      "nss_port2_tx_clk",
					      "nss_port3_rx_clk",
					      "nss_port3_tx_clk",
					      "nss_port4_rx_clk",
					      "nss_port4_tx_clk",
					      "nss_port5_rx_clk",
					      "nss_port5_tx_clk",
					      "nss_port6_rx_clk",
					      "nss_port6_tx_clk",
					      "uniphy0_port1_rx_clk",
					      "uniphy0_port1_tx_clk",
					      "uniphy0_port2_rx_clk",
					      "uniphy0_port2_tx_clk",
					      "uniphy0_port3_rx_clk",
					      "uniphy0_port3_tx_clk",
					      "uniphy0_port4_rx_clk",
					      "uniphy0_port4_tx_clk",
					      "uniphy1_port5_rx_clk",
					      "uniphy1_port5_tx_clk",
					      "uniphy2_port6_rx_clk",
					      "uniphy2_port6_tx_clk";
				resets = <&nsscc NSS_CC_PPE_BCR>,
					 <&gcc GCC_UNIPHY0_BCR>,
					 <&gcc GCC_UNIPHY1_BCR>,
					 <&gcc GCC_UNIPHY2_BCR>,
					 <&gcc GCC_UNIPHY0_AHB_ARES>,
					 <&gcc GCC_UNIPHY1_AHB_ARES>,
					 <&gcc GCC_UNIPHY2_AHB_ARES>,
					 <&gcc GCC_UNIPHY0_SYS_ARES>,
					 <&gcc GCC_UNIPHY1_SYS_ARES>,
					 <&gcc GCC_UNIPHY2_SYS_ARES>,
					 <&gcc GCC_UNIPHY0_XPCS_ARES>,
					 <&gcc GCC_UNIPHY1_XPCS_ARES>,
					 <&gcc GCC_UNIPHY2_XPCS_ARES>,
					 <&nsscc NSS_CC_UNIPHY_PORT1_RX_CLK_ARES>,
					 <&nsscc NSS_CC_UNIPHY_PORT1_TX_CLK_ARES>,
					 <&nsscc NSS_CC_UNIPHY_PORT2_RX_CLK_ARES>,
					 <&nsscc NSS_CC_UNIPHY_PORT2_TX_CLK_ARES>,
					 <&nsscc NSS_CC_UNIPHY_PORT3_RX_CLK_ARES>,
					 <&nsscc NSS_CC_UNIPHY_PORT3_TX_CLK_ARES>,
					 <&nsscc NSS_CC_UNIPHY_PORT4_RX_CLK_ARES>,
					 <&nsscc NSS_CC_UNIPHY_PORT4_TX_CLK_ARES>,
					 <&nsscc NSS_CC_UNIPHY_PORT5_RX_CLK_ARES>,
					 <&nsscc NSS_CC_UNIPHY_PORT5_TX_CLK_ARES>,
					 <&nsscc NSS_CC_UNIPHY_PORT6_RX_CLK_ARES>,
					 <&nsscc NSS_CC_UNIPHY_PORT6_TX_CLK_ARES>,
					 <&nsscc NSS_CC_PORT1_RX_CLK_ARES>,
					 <&nsscc NSS_CC_PORT1_TX_CLK_ARES>,
					 <&nsscc NSS_CC_PORT2_RX_CLK_ARES>,
					 <&nsscc NSS_CC_PORT2_TX_CLK_ARES>,
					 <&nsscc NSS_CC_PORT3_RX_CLK_ARES>,
					 <&nsscc NSS_CC_PORT3_TX_CLK_ARES>,
					 <&nsscc NSS_CC_PORT4_RX_CLK_ARES>,
					 <&nsscc NSS_CC_PORT4_TX_CLK_ARES>,
					 <&nsscc NSS_CC_PORT5_RX_CLK_ARES>,
					 <&nsscc NSS_CC_PORT5_TX_CLK_ARES>,
					 <&nsscc NSS_CC_PORT6_RX_CLK_ARES>,
					 <&nsscc NSS_CC_PORT6_TX_CLK_ARES>,
					 <&nsscc NSS_CC_PORT1_MAC_CLK_ARES>,
					 <&nsscc NSS_CC_PORT2_MAC_CLK_ARES>,
					 <&nsscc NSS_CC_PORT3_MAC_CLK_ARES>,
					 <&nsscc NSS_CC_PORT4_MAC_CLK_ARES>,
					 <&nsscc NSS_CC_PORT5_MAC_CLK_ARES>,
					 <&nsscc NSS_CC_PORT6_MAC_CLK_ARES>;
				reset-names = "ppe_rst",
					      "uniphy0_soft_rst",
					      "uniphy1_soft_rst",
					      "uniphy2_soft_rst",
					      "uniphy0_ahb_rst",
					      "uniphy1_ahb_rst",
					      "uniphy2_ahb_rst",
					      "uniphy0_sys_rst",
					      "uniphy1_sys_rst",
					      "uniphy2_sys_rst",
					      "uniphy0_xpcs_rst",
					      "uniphy1_xpcs_rst",
					      "uniphy2_xpcs_rst",
					      "uniphy_port1_rx_rst",
					      "uniphy_port1_tx_rst",
					      "uniphy_port2_rx_rst",
					      "uniphy_port2_tx_rst",
					      "uniphy_port3_rx_rst",
					      "uniphy_port3_tx_rst",
					      "uniphy_port4_rx_rst",
					      "uniphy_port4_tx_rst",
					      "uniphy_port5_rx_rst",
					      "uniphy_port5_tx_rst",
					      "uniphy_port6_rx_rst",
					      "uniphy_port6_tx_rst",
					      "nss_port1_rx_rst",
					      "nss_port1_tx_rst",
					      "nss_port2_rx_rst",
					      "nss_port2_tx_rst",
					      "nss_port3_rx_rst",
					      "nss_port3_tx_rst",
					      "nss_port4_rx_rst",
					      "nss_port4_tx_rst",
					      "nss_port5_rx_rst",
					      "nss_port5_tx_rst",
					      "nss_port6_rx_rst",
					      "nss_port6_tx_rst",
					      "nss_port1_mac_rst",
					      "nss_port2_mac_rst",
					      "nss_port3_mac_rst",
					      "nss_port4_mac_rst",
					      "nss_port5_mac_rst",
					      "nss_port6_mac_rst";

				port_scheduler_resource {
					port@0 {
						port_id = <0>;
						ucast_queue = <128 255>;
						mcast_queue = <256 263>;
						l0sp = <26 41>;
						l0cdrr = <128 255>;
						l0edrr = <128 255>;
						l1cdrr = <26 41>;
						l1edrr = <26 41>;
					};

					port@1 {
						port_id = <1>;
						ucast_queue = <0 7>;
						mcast_queue = <272 275>;
						l0sp = <0 1>;
						l0cdrr = <0 7>;
						l0edrr = <0 7>;
						l1cdrr = <0 1>;
						l1edrr = <0 1>;
					};

					port@2 {
						port_id = <2>;
						ucast_queue = <8 15>;
						mcast_queue = <276 279>;
						l0sp = <2 3>;
						l0cdrr = <8 15>;
						l0edrr = <8 15>;
						l1cdrr = <2 3>;
						l1edrr = <2 3>;
					};

					port@3 {
						port_id = <3>;
						ucast_queue = <16 23>;
						mcast_queue = <280 283>;
						l0sp = <4 5>;
						l0cdrr = <16 23>;
						l0edrr = <16 23>;
						l1cdrr = <4 5>;
						l1edrr = <4 5>;
					};

					port@4 {
						port_id = <4>;
						ucast_queue = <24 31>;
						mcast_queue = <284 287>;
						l0sp = <6 7>;
						l0cdrr = <24 31>;
						l0edrr = <24 31>;
						l1cdrr = <6 7>;
						l1edrr = <6 7>;
					};

					port@5 {
						port_id = <5>;
						ucast_queue = <32 39>;
						mcast_queue = <288 291>;
						l0sp = <8 9>;
						l0cdrr = <32 39>;
						l0edrr = <32 39>;
						l1cdrr = <8 9>;
						l1edrr = <8 9>;
					};

					port@6 {
						port_id = <6>;
						ucast_queue = <40 71>;
						mcast_queue = <292 295>;
						l0sp = <10 17>;
						l0cdrr = <40 71>;
						l0edrr = <40 71>;
						l1cdrr = <10 17>;
						l1edrr = <10 17>;
					};

					port@7 {
						port_id = <7>;
						ucast_queue = <72 79>;
						mcast_queue = <296 297>;
						l0sp = <18 19>;
						l0cdrr = <72 79>;
						l0edrr = <72 79>;
						l1cdrr = <18 19>;
						l1edrr = <18 19>;
					};

					port@8 {
						port_id = <8>;
						ucast_queue = <80 127>;
						mcast_queue = <298 299>;
						l0sp = <20 25>;
						l0cdrr = <80 127>;
						l0edrr = <80 127>;
						l1cdrr = <20 25>;
						l1edrr = <20 25>;
					};

					reserved {
						ucast_queue = <0 0>;
						mcast_queue = <0 0>;
						l0sp = <42 63>;
						l0cdrr = <0 0>;
						l0edrr = <0 0>;
						l1cdrr = <42 63>;
						l1edrr = <42 63>;
					};
				};

				port_scheduler_config {
					port@0 {
						port_id = <0>;

						l1scheduler {
							group@0 {
								/* L0 SP */
								sp = <26>;
								sp_loop_pri = <16>;
								sp_max_pri = <1>;
								/* cpri cdrr epri edrr */
								cfg = <0 26 0 26>;
							};
						};

						l0scheduler {
							group@0 {
								/* (5 cores + 4 VPs) + 1 SMD host groups with 8 priorities */
								ucast_queue = <128>;
								ucast_loop_pri = <80>;
								ucast_max_pri = <8>;
								/* multicast queue */
								mcast_queue = <256>;
								mcast_loop_pri = <8>;
								/* sp cpri cdrr epri edrr */
								cfg = <26 0 128 0 128>;
							};

							group@1 {
								/* GRO group */
								ucast_queue = <208>;
								ucast_loop_pri = <8>;
								cfg = <36 0 208 0 208>;
							};

							group@2 {
								/* SMD DS group */
								ucast_queue = <216>;
								ucast_loop_pri = <8>;
								cfg = <37 0 216 0 216>;
							};

							group@3 {
								/* 4 SSID groups with 8 priorities. */
								ucast_queue = <224>;
								ucast_loop_pri = <32>;
								ucast_max_pri = <8>;
								cfg = <38 0 224 0 224>;
							};

							group@4 {
								/* IGSRAM for DDRQ LAN to WAN with 8 priorities. */
								ucast_queue = <216>;
								ucast_loop_pri = <8>;
								ucast_max_pri = <8>;
								cfg = <40 0 216 0 216>;
							};

							group@5 {
								/* IGSRAM for DDRQ WAN to LAN with 8 priorities. */
								ucast_queue = <224>;
								ucast_loop_pri = <8>;
								ucast_max_pri = <8>;
								cfg = <41 0 224 0 224>;
							};

							group@6 {
								/* IGSRAM for DDRQ DS to WAN with 1 priority. */
								ucast_queue = <232>;
								cfg = <42 0 232 0 232>;
							};
						};
					};

					port@1 {
						port_id = <1>;

						l1scheduler {
							group@0 {
								sp = <0>;
								cfg = <0 0 0 0>;
							};
						};

						l0scheduler {
							group@0 {
								ucast_queue = <0>;
								ucast_loop_pri = <8>;
								mcast_queue = <272>;
								mcast_loop_pri = <4>;
								cfg = <0 0 0 0 0>;
							};
						};
					};

					port@2 {
						port_id = <2>;

						l1scheduler {
							group@0 {
								sp = <2>;
								cfg = <0 2 0 2>;
							};
						};

						l0scheduler {
							group@0 {
								ucast_queue = <8>;
								ucast_loop_pri = <8>;
								mcast_queue = <276>;
								mcast_loop_pri = <4>;
								cfg = <2 0 8 0 8>;
							};
						};
					};

					port@3 {
						port_id = <3>;

						l1scheduler {
							group@0 {
								sp = <4>;
								cfg = <0 4 0 4>;
							};
						};

						l0scheduler {
							group@0 {
								ucast_queue = <16>;
								ucast_loop_pri = <8>;
								mcast_queue = <280>;
								mcast_loop_pri = <4>;
								cfg = <4 0 16 0 16>;
							};
						};
					};

					port@4 {
						port_id = <4>;

						l1scheduler {
							group@0 {
								sp = <6>;
								cfg = <0 6 0 6>;
							};
						};

						l0scheduler {
							group@0 {
								ucast_queue = <24>;
								ucast_loop_pri = <8>;
								mcast_queue = <284>;
								mcast_loop_pri = <4>;
								cfg = <6 0 24 0 24>;
							};
						};
					};

					port@5 {
						port_id = <5>;

						l1scheduler {
							group@0 {
								sp = <8>;
								cfg = <0 8 0 8>;
							};
						};

						l0scheduler {
							group@0 {
								ucast_queue = <32>;
								ucast_loop_pri = <8>;
								mcast_queue = <288>;
								mcast_loop_pri = <4>;
								cfg = <8 0 32 0 32>;
							};
						};
					};

					port@6 {
						port_id = <6>;

						l1scheduler {
							group@0 {
								sp = <10>;
								sp_loop_pri = <4>;
								sp_max_pri = <1>;
								cfg = <0 10 0 10>;
							};
						};

						l0scheduler {
							group@0 {
								ucast_queue = <40>;
								ucast_loop_pri = <32>;
								ucast_max_pri = <8>;
								mcast_queue = <292>;
								mcast_loop_pri = <4>;
								cfg = <10 0 40 0 40>;
							};
						};
					};

					port@7 {
						port_id = <7>;

						l1scheduler {
							group@0 {
								sp = <18>;
								cfg = <0 18 0 18>;
							};
						};

						l0scheduler {
							group@0 {
								ucast_queue = <72>;
								ucast_loop_pri = <8>;
								mcast_queue = <296>;
								mcast_loop_pri = <2>;
								cfg = <18 0 72 0 72>;
							};
						};
					};

					port@8 {
						port_id = <8>;

						l1scheduler {
							group@0 {
								sp = <20>;
								sp_loop_pri = <6>;
								sp_max_pri = <1>;
								cfg = <0 20 0 20>;
							};
						};

						l0scheduler {
							group@0 {
								ucast_queue = <80>;
								ucast_loop_pri = <48>;
								ucast_max_pri = <8>;
								mcast_queue = <298>;
								mcast_loop_pri = <2>;
								cfg = <20 0 80 0 80>;
							};
						};
					};
				};
			};
		};

		edma@2ad00000 {
			compatible = "qcom,edma";
			reg = <0x2ad00000 0x1c5000>;
			reg-names = "edma-reg-base";
			/* TO-DO: Add EDMA HW resets */
			reset-names = "edma_rst";
		};

		nss-ppe {
			compatible = "qcom,nss-ppe";
		};
	};

	timer {
		compatible = "arm,armv8-timer";
		interrupts = <GIC_PPI 13 (GIC_CPU_MASK_SIMPLE(4) | IRQ_TYPE_LEVEL_LOW)>,
			     <GIC_PPI 14 (GIC_CPU_MASK_SIMPLE(4) | IRQ_TYPE_LEVEL_LOW)>,
			     <GIC_PPI 11 (GIC_CPU_MASK_SIMPLE(4) | IRQ_TYPE_LEVEL_LOW)>,
			     <GIC_PPI 10 (GIC_CPU_MASK_SIMPLE(4) | IRQ_TYPE_LEVEL_LOW)>,
			     <GIC_PPI 12 (GIC_CPU_MASK_SIMPLE(4) | IRQ_TYPE_LEVEL_LOW)>;
	};

	qcom,test@0 {
		compatible = "qcom,testmhi";
		qcom,wlan-ramdump-dynamic = <0x600000>;
	};
};
